VERSION ""

NS_ :

BS_:

BU_: Device Host

BO_ 2515949566 ClimateHMIState: 6 Vector__XXX
 SG_ ClimateSystemEffortDisp : 40|8@1+ (1,-100) [-100|100] "%" Vector__XXX
 SG_ TurboEnableState : 24|2@1+ (1,0) [0|3] "" Vector__XXX
 SG_ AutoEnableState : 16|2@1+ (1,0) [0|3] "" Vector__XXX
 SG_ IsolationValveIntegrityFault : 38|1@1+ (1,0) [0|1] "" Vector__XXX
 SG_ AmbientTempSensorIntegrity : 31|1@1+ (1,0) [0|1] "" Vector__XXX
 SG_ WindscreenFlapIntegrityFault : 35|1@1+ (1,0) [0|1] "" Vector__XXX
 SG_ ACEnableState : 18|2@1+ (1,0) [0|3] "" Vector__XXX
 SG_ MaxACState : 20|2@1+ (1,0) [0|3] "" Vector__XXX
 SG_ PetModeState : 22|2@1+ (1,0) [0|3] "" Vector__XXX
 SG_ HVACFailure : 26|1@1+ (1,0) [0|1] "" Vector__XXX
 SG_ CabinTempSensorIntegrityFault : 30|1@1+ (1,0) [0|1] "" Vector__XXX
 SG_ RainLightSensorIntegrityFault : 32|1@1+ (1,0) [0|1] "" Vector__XXX
 SG_ FrontFlapIntegrityFault : 36|1@1+ (1,0) [0|1] "" Vector__XXX
 SG_ FloorFlapIntegrityFault : 37|1@1+ (1,0) [0|1] "" Vector__XXX
 SG_ RecircFlapIntegrityFault : 34|1@1+ (1,0) [0|1] "" Vector__XXX
 SG_ BlowerIntegrityFault : 33|1@1+ (1,0) [0|1] "" Vector__XXX
 SG_ TAirOutSensorIntegrityFault : 29|1@1+ (1,0) [0|1] "" Vector__XXX
 SG_ TAirInSensorIntegrityFault : 27|1@1+ (1,0) [0|1] "" Vector__XXX
 SG_ TChillerCoreSensorIntegrityFault : 28|1@1+ (1,0) [0|1] "" Vector__XXX
 SG_ DemistRequestState : 2|2@1+ (1,0) [0|3] "" Vector__XXX
 SG_ OutletSelectionState : 8|4@1+ (1,0) [0|15] "" Vector__XXX
 SG_ ClimateControlEnableState : 0|2@1+ (1,0) [0|3] "" Vector__XXX
 SG_ BlowerSpeedRequestState : 4|4@1+ (1,0) [0|15] "" Vector__XXX
 SG_ RecirculationRequestState : 12|3@1+ (1,0) [0|7] "" Vector__XXX

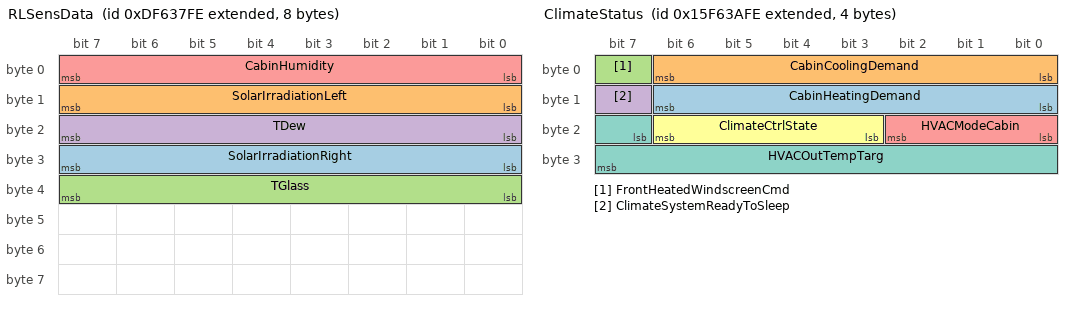
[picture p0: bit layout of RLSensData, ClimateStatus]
BO_ 2381723646 RLSensData: 8 Vector__XXX
 SG_ SolarIrradiationRight : 24|8@1+ (5,0) [0|1250] "W/m2" Vector__XXX
 SG_ SolarIrradiationLeft : 8|8@1+ (5,0) [0|1250] "W/m2" Vector__XXX
 SG_ TGlass : 32|8@1+ (0.5,-20) [-20|100] "degC" Vector__XXX
 SG_ TDew : 16|8@1+ (0.5,-20) [-20|100] "degC" Vector__XXX
 SG_ CabinHumidity : 0|8@1+ (0.5,0) [0|125] "%" Vector__XXX

BO_ 2515942142 ClimateStatus: 4 Vector__XXX
 SG_ CabinHeatingDemand : 8|7@1+ (1,0) [0|100] "%" Vector__XXX
 SG_ CabinCoolingDemand : 0|7@1+ (1,0) [0|100] "%" Vector__XXX
 SG_ FrontHeatedWindscreenCmd : 7|1@1+ (1,0) [0|1] "" Vector__XXX
 SG_ ClimateSystemReadyToSleep : 15|1@1+ (1,0) [0|1] "" Vector__XXX
 SG_ HVACModeCabin : 16|3@1+ (1,0) [0|0] "" Vector__XXX
 SG_ ClimateCtrlState : 19|4@1+ (1,0) [0|0] "" Vector__XXX
 SG_ HVACOutTempTarg : 23|9@1+ (0.2,-10) [-10|92.2] "degC" Vector__XXX

BO_ 2515944190 Reserved2: 8 Vector__XXX

BO_ 2515943934 Reserved1: 8 Vector__XXX

BO_ 2515942654 ClimateTempData: 3 Vector__XXX
 SG_ CabinTempSensorFault : 16|1@1+ (1,0) [0|1] "" Vector__XXX
 SG_ ActualCabinTemperature : 0|16@1+ (0.03125,-273) [-273|1774.96875] "degC" Vector__XXX

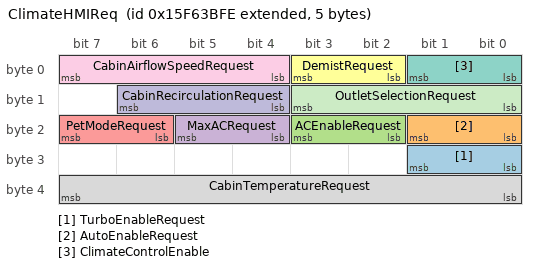
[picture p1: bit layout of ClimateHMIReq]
BO_ 2515942398 ClimateHMIReq: 5 Vector__XXX
 SG_ TurboEnableRequest : 24|2@1+ (1,0) [0|3] "" Vector__XXX
 SG_ AutoEnableRequest : 16|2@1+ (1,0) [0|3] "" Vector__XXX
 SG_ ACEnableRequest : 18|2@1+ (1,0) [0|3] "" Vector__XXX
 SG_ MaxACRequest : 20|2@1+ (1,0) [0|3] "" Vector__XXX
 SG_ PetModeRequest : 22|2@1+ (1,0) [0|3] "" Vector__XXX
 SG_ DemistRequest : 2|2@1+ (1,0) [0|3] "" Vector__XXX
 SG_ ClimateControlEnable : 0|2@1+ (1,0) [0|3] "" Vector__XXX
 SG_ CabinTemperatureRequest : 32|8@1+ (0.25,0) [0|63.75] "degC" Vector__XXX
 SG_ CabinAirflowSpeedRequest : 4|4@1+ (1,0) [0|15] "" Vector__XXX
 SG_ CabinRecirculationRequest : 12|3@1+ (1,0) [0|7] "" Vector__XXX
 SG_ OutletSelectionRequest : 8|4@1+ (1,0) [0|15] "" Vector__XXX

CM_ "$File: //depot/auto/dbc/Software_Modules/Thermal_System/Climate_System/0.3.1.0/Climate_System.dbc $
$Change: 215985 $
$DateTime: 2024/08/21 10:12:14 $
$Revision: #1 $";
CM_ BO_ 2515942142 "Cabin Climate Controller State";
CM_ BO_ 2515944190 "Cabin Climate HVAC Request";
CM_ BO_ 2515943934 "Cabin Climate HVAC Request";
CM_ BO_ 2515942654 "Cabin Climate Temperature State";
BA_DEF_  "BusType" STRING ;
BA_DEF_  "DBName" STRING ;
BA_DEF_  "DatabaseVersion" STRING ;
BA_DEF_ BO_  "GenMsgCycleTime" INT 0 3600000;
BA_DEF_ BO_  "GenMsgILSupport" ENUM  "No","Yes";
BA_DEF_ BO_  "GenMsgRequestable" INT 0 1;
BA_DEF_ BO_  "GenMsgSendType" ENUM  "cyclic","NotUsed","NotUsed","NotUsed","NotUsed","NotUsed","NotUsed","IfActive","noMsgSendType";
BA_DEF_ SG_  "GenSigEVName" STRING ;
BA_DEF_ SG_  "GenSigILSupport" ENUM  "No","Yes";
BA_DEF_ SG_  "GenSigSendType" ENUM  "Cyclic","OnWrite","OnWriteWithRepetition","OnChange","OnChangeWithRepetition","IfActive","IfActiveWithRepetition","NoSigSendType";
BA_DEF_ SG_  "GenSigStartValue" INT 0 2147483647;
BA_DEF_ BU_  "NmStationAddress" INT 0 255;
BA_DEF_  "ProtocolType" STRING ;
BA_DEF_  "SAE_J1939_21_SpecVersion" STRING ;
BA_DEF_  "SAE_J1939_71_SpecVersion" STRING ;
BA_DEF_  "SAE_J1939_73_SpecVersion" STRING ;
BA_DEF_  "SAE_J1939_75_SpecVersion" STRING ;
BA_DEF_  "SAE_J1939_81_SpecVersion" STRING ;
BA_DEF_  "SAE_J1939_DA_SpecVersion" STRING ;
BA_DEF_ BO_  "Producer" STRING ;
BA_DEF_ SG_  "SigType" ENUM  "Default","Range","RangeSigned","ASCII","Discrete","Control","ReferencePGN","DTC","StringDelimiter","StringLength","StringLengthControl","MessageCounter","MessageChecksum";
BA_DEF_ BO_  "VFrameFormat" ENUM  "StandardCAN","ExtendedCAN","reserved","J1939PG","reserved","reserved","reserved","reserved","reserved","reserved","reserved","reserved","reserved","reserved","StandardCAN_FD","ExtendedCAN_FD";
BA_DEF_DEF_  "BusType" "";
BA_DEF_DEF_  "DBName" "Climate_System";
BA_DEF_DEF_  "DatabaseVersion" "";
BA_DEF_DEF_  "GenMsgCycleTime" 0;
BA_DEF_DEF_  "GenMsgILSupport" "Yes";
BA_DEF_DEF_  "GenMsgRequestable" 1;
BA_DEF_DEF_  "GenMsgSendType" "noMsgSendType";
BA_DEF_DEF_  "GenSigEVName" "Env@Nodename_@Signame";
BA_DEF_DEF_  "GenSigILSupport" "Yes";
BA_DEF_DEF_  "GenSigSendType" "NoSigSendType";
BA_DEF_DEF_  "GenSigStartValue" 0;
BA_DEF_DEF_  "NmStationAddress" 254;
BA_DEF_DEF_  "ProtocolType" "";
BA_DEF_DEF_  "SAE_J1939_21_SpecVersion" "";
BA_DEF_DEF_  "SAE_J1939_71_SpecVersion" "";
BA_DEF_DEF_  "SAE_J1939_73_SpecVersion" "";
BA_DEF_DEF_  "SAE_J1939_75_SpecVersion" "";
BA_DEF_DEF_  "SAE_J1939_81_SpecVersion" "";
BA_DEF_DEF_  "SAE_J1939_DA_SpecVersion" "";
BA_DEF_DEF_  "Producer" "TMS";
BA_DEF_DEF_  "SigType" "Default";
BA_DEF_DEF_  "VFrameFormat" "J1939PG";
BA_ "SAE_J1939_DA_SpecVersion" "2015-01";
BA_ "SAE_J1939_81_SpecVersion" "2012-05";
BA_ "SAE_J1939_75_SpecVersion" "2012-05";
BA_ "SAE_J1939_73_SpecVersion" "2012-10";
BA_ "SAE_J1939_71_SpecVersion" "2012-10";
BA_ "SAE_J1939_21_SpecVersion" "2006-10";
BA_ "ProtocolType" "J1939";
BA_ "DatabaseVersion" "1.0";
BA_ "BusType" "CAN";
BA_ "GenMsgCycleTime" BO_ 2515949566 500;
BA_ "GenMsgSendType" BO_ 2515949566 0;
BA_ "Producer" BO_ 2381723646 "ELS";
BA_ "GenMsgCycleTime" BO_ 2381723646 1000;
BA_ "GenMsgSendType" BO_ 2381723646 0;
BA_ "GenMsgSendType" BO_ 2515942142 0;
BA_ "GenMsgCycleTime" BO_ 2515942142 250;
BA_ "GenMsgSendType" BO_ 2515944190 0;
BA_ "GenMsgCycleTime" BO_ 2515944190 250;
BA_ "GenMsgSendType" BO_ 2515943934 0;
BA_ "GenMsgCycleTime" BO_ 2515943934 250;
BA_ "GenMsgSendType" BO_ 2515942654 0;
BA_ "GenMsgCycleTime" BO_ 2515942654 1000;
BA_ "Producer" BO_ 2515942398 "HMI";
BA_ "GenMsgSendType" BO_ 2515942398 0;
BA_ "GenMsgCycleTime" BO_ 2515942398 500;
BA_ "GenSigStartValue" SG_ 2515949566 ClimateSystemEffortDisp 100;
BA_ "GenSigStartValue" SG_ 2515949566 TurboEnableState 3;
BA_ "GenSigStartValue" SG_ 2515949566 AutoEnableState 3;
BA_ "GenSigStartValue" SG_ 2515949566 ACEnableState 3;
BA_ "GenSigStartValue" SG_ 2515949566 MaxACState 3;
BA_ "GenSigStartValue" SG_ 2515949566 PetModeState 3;
BA_ "GenSigStartValue" SG_ 2515949566 DemistRequestState 3;
BA_ "GenSigStartValue" SG_ 2515949566 OutletSelectionState 15;
BA_ "GenSigStartValue" SG_ 2515949566 ClimateControlEnableState 3;
BA_ "GenSigStartValue" SG_ 2515949566 BlowerSpeedRequestState 15;
BA_ "GenSigStartValue" SG_ 2515949566 RecirculationRequestState 7;
BA_ "SigType" SG_ 2381723646 SolarIrradiationRight 1;
BA_ "SigType" SG_ 2381723646 SolarIrradiationLeft 1;
BA_ "GenSigStartValue" SG_ 2381723646 TGlass 40;
BA_ "SigType" SG_ 2381723646 TGlass 1;
BA_ "GenSigStartValue" SG_ 2381723646 TDew 40;
BA_ "SigType" SG_ 2381723646 CabinHumidity 1;
BA_ "GenSigStartValue" SG_ 2515942142 HVACOutTempTarg 50;
BA_ "GenSigStartValue" SG_ 2515942654 ActualCabinTemperature 8736;
BA_ "GenSigStartValue" SG_ 2515942398 TurboEnableRequest 3;
BA_ "GenSigStartValue" SG_ 2515942398 AutoEnableRequest 3;
BA_ "GenSigStartValue" SG_ 2515942398 ACEnableRequest 3;
BA_ "GenSigStartValue" SG_ 2515942398 MaxACRequest 3;
BA_ "GenSigStartValue" SG_ 2515942398 PetModeRequest 3;
BA_ "GenSigStartValue" SG_ 2515942398 DemistRequest 3;
BA_ "GenSigStartValue" SG_ 2515942398 ClimateControlEnable 3;
BA_ "GenSigStartValue" SG_ 2515942398 CabinTemperatureRequest 84;
BA_ "GenSigStartValue" SG_ 2515942398 CabinAirflowSpeedRequest 15;
BA_ "GenSigStartValue" SG_ 2515942398 CabinRecirculationRequest 7;
BA_ "GenSigStartValue" SG_ 2515942398 OutletSelectionRequest 15;
VAL_ 2515949566 TurboEnableState 2 "Error" 3 "Not Available" 1 "On" 0 "Off" ;
VAL_ 2515949566 AutoEnableState 2 "Error" 3 "Not Available" 1 "On" 0 "Off" ;
VAL_ 2515949566 ACEnableState 2 "Error" 3 "Not Available" 1 "On" 0 "Off" ;
VAL_ 2515949566 MaxACState 2 "Error" 3 "Not Available" 1 "On" 0 "Off" ;
VAL_ 2515949566 PetModeState 2 "Error" 3 "Not Available" 1 "On" 0 "Off" ;
VAL_ 2515949566 DemistRequestState 2 "Error" 3 "Not Available" 1 "On" 0 "Off" ;
VAL_ 2515949566 OutletSelectionState 15 "NA" 14 "Error" 8 "Auto" 6 "Windscreen/Front" 7 "Windscreen/Front/Floor" 5 "Windscreen/Floor" 4 "Front/Floor" 3 "Floor" 2 "Front" 1 "Windscreen" 0 "Off" ;
VAL_ 2515949566 ClimateControlEnableState 2 "Error" 3 "Not Available" 1 "On" 0 "Off" ;
VAL_ 2515949566 BlowerSpeedRequestState 15 "NA" 14 "Error" 10 "Auto" 9 "Level 9" 8 "Level 8" 7 "Level 7" 6 "Level 6" 5 "Level 5" 4 "Level 4" 3 "Level 3" 2 "Level 2" 1 "Level 1" 0 "Off" ;
VAL_ 2515949566 RecirculationRequestState 7 "NA" 6 "Error" 2 "Auto" 1 "FullRecirc" 0 "Fresh" ;
VAL_ 2515942142 HVACModeCabin 7 "NotAvailable" 4 "Ventilation" 3 "Demist" 2 "Heating" 1 "Cooling" 0 "Standby" ;
VAL_ 2515942142 ClimateCtrlState 15 "NA" 7 "Demist" 6 "Turbo" 5 "TurboToAuto" 4 "Auto" 3 "Manual" 2 "PreShutdown" 1 "Off" 0 "Init" ;
VAL_ 2515942398 TurboEnableRequest 2 "Error" 3 "Not Available" 1 "On" 0 "Off" ;
VAL_ 2515942398 AutoEnableRequest 2 "Error" 3 "Not Available" 1 "On" 0 "Off" ;
VAL_ 2515942398 ACEnableRequest 2 "Error" 3 "Not Available" 1 "On" 0 "Off" ;
VAL_ 2515942398 MaxACRequest 2 "Error" 3 "Not Available" 1 "On" 0 "Off" ;
VAL_ 2515942398 PetModeRequest 2 "Error" 3 "Not Available" 1 "On" 0 "Off" ;
VAL_ 2515942398 DemistRequest 2 "Error" 3 "Not Available" 1 "On" 0 "Off" ;
VAL_ 2515942398 ClimateControlEnable 2 "Error" 3 "Not Available" 1 "On" 0 "Off" ;
VAL_ 2515942398 CabinAirflowSpeedRequest 15 "NA" 14 "Error" 10 "Auto" 9 "Level 9" 8 "Level 8" 7 "Level 7" 6 "Level 6" 5 "Level 5" 4 "Level 4" 3 "Level 3" 2 "Level 2" 1 "Level 1" 0 "Off" ;
VAL_ 2515942398 CabinRecirculationRequest 7 "NA" 6 "Error" 2 "Auto" 1 "FullRecirc" 0 "Fresh" ;
VAL_ 2515942398 OutletSelectionRequest 15 "NA" 14 "Error" 8 "Auto" 6 "Windscreen/Front" 7 "Windscreen/Front/Floor" 5 "Windscreen/Floor" 4 "Front/Floor" 3 "Floor" 2 "Front" 1 "Windscreen" 0 "Off" ;
